VERSION ""

NS_ :

BS_:

BU_: MASTER SENSOR GEO ANDROID MOTOR

BO_ 120 HEARTBEAT: 1 MASTER
 SG_ HEARTBEAT_cmd : 0|8@1+ (1,0) [0|0] "" SENSOR,MOTOR,ANDROID,GEO

BO_ 125 MASTER_REQUEST: 1 MASTER
 SG_ MASTER_REQUEST_cmd : 0|4@1+ (1,0) [0|0] "" ANDROID

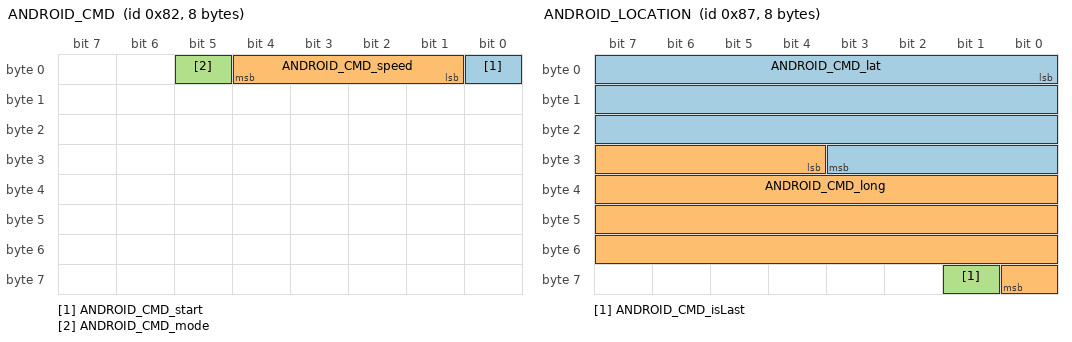
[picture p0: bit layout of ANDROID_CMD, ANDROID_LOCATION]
BO_ 130 ANDROID_CMD: 8 ANDROID
 SG_ ANDROID_CMD_start : 0|1@1+ (1,0) [0|0] "" MASTER,MOTOR
 SG_ ANDROID_CMD_speed : 1|4@1+ (1,0) [0|0] "kmph" MASTER,MOTOR
 SG_ ANDROID_CMD_mode : 5|1@1+ (1,0) [0|0] "" MASTER,MOTOR

BO_ 135 ANDROID_LOCATION: 8 ANDROID
 SG_ ANDROID_CMD_lat : 0|28@1+ (0.000001,-90.000000) [-90|90] "Degrees" MASTER,MOTOR,GEO
 SG_ ANDROID_CMD_long : 28|29@1+ (0.000001,-180.000000) [-180|180] "Degrees" MASTER,MOTOR,GEO
 SG_ ANDROID_CMD_isLast : 57|1@1+ (1,0) [0|0] "" MASTER,MOTOR,GEO

BO_ 140 CAR_CONTROL: 2 MASTER
 SG_ CAR_CONTROL_speed : 0|8@1+ (1,0) [0|0] "mph" MOTOR
 SG_ CAR_CONTROL_steer : 8|8@1+ (1,0) [0|0] "" MOTOR

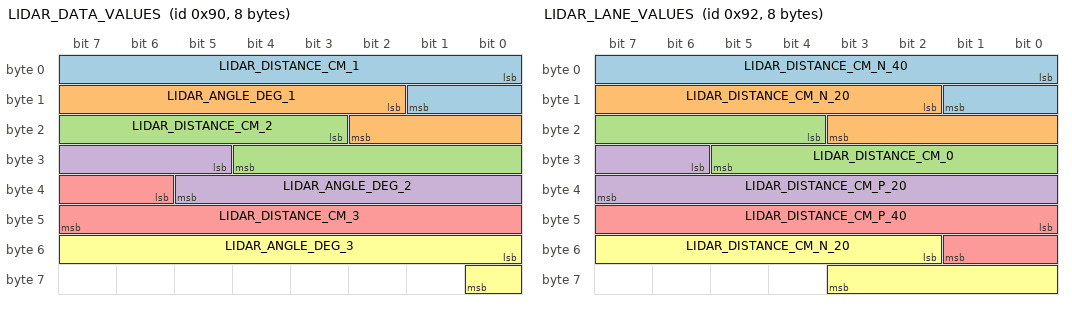
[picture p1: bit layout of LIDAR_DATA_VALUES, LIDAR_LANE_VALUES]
BO_ 144 LIDAR_DATA_VALUES: 8 SENSOR
 SG_ LIDAR_DISTANCE_CM_1 : 0|10@1+ (1,0) [0|600] "" MASTER,MOTOR,ANDROID
 SG_ LIDAR_ANGLE_DEG_1 : 10|9@1+ (1,0) [0|360] "" MASTER,MOTOR,ANDROID
 SG_ LIDAR_DISTANCE_CM_2 : 19|10@1+ (1,0) [0|600] "" MASTER,MOTOR,ANDROID
 SG_ LIDAR_ANGLE_DEG_2 : 29|9@1+ (1,0) [0|360] "" MASTER,MOTOR,ANDROID
 SG_ LIDAR_DISTANCE_CM_3 : 38|10@1+ (1,0) [0|600] "" MASTER,MOTOR,ANDROID
 SG_ LIDAR_ANGLE_DEG_3 : 48|9@1+ (1,0) [0|360] "" MASTER,MOTOR,ANDROID

BO_ 145 SENSOR_VALUES: 4 SENSOR
 SG_ LIDAR_DISTANCE_CM : 0|10@1+ (1,0) [0|600] "" MASTER,MOTOR,ANDROID
 SG_ LIDAR_ANGLE_DEG : 10|9@1+ (1,0) [0|360] "" MASTER,MOTOR,ANDROID
 SG_ LIDAR_QUALITY_DEG : 19|10@1+ (1,0) [0|128] "" MASTER,MOTOR,ANDROID
 SG_ LIDAR_DISTANCE_CM_P_180 : 30|10@1+ (1,0) [0|600] "" MASTER,MOTOR,ANDROID
 SG_ LIDAR_DISTANCE_CM_N_160 : 40|10@1+ (1,0) [0|600] "" MASTER,MOTOR,ANDROID
 SG_ LIDAR_DISTANCE_CM_N_140 : 50|10@1+ (1,0) [0|600] "" MASTER,MOTOR,ANDROID

BO_ 146 LIDAR_LANE_VALUES: 8 SENSOR
 SG_ LIDAR_DISTANCE_CM_N_40 : 0|10@1+ (1,0) [0|600] "" MASTER,MOTOR,ANDROID
 SG_ LIDAR_DISTANCE_CM_N_20 : 10|10@1+ (1,0) [0|600] "" MASTER,MOTOR,ANDROID
 SG_ LIDAR_DISTANCE_CM_0 : 20|10@1+ (1,0) [0|600] "" MASTER,MOTOR,ANDROID
 SG_ LIDAR_DISTANCE_CM_P_20 : 30|10@1+ (1,0) [0|600] "" MASTER,MOTOR,ANDROID
 SG_ LIDAR_DISTANCE_CM_P_40 : 40|10@1+ (1,0) [0|600] "" MASTER,MOTOR,ANDROID
 SG_ LIDAR_DISTANCE_CM_N_20 : 50|10@1+ (1,0) [0|600] "" MASTER,MOTOR,ANDROID
BO_ 150 SENSOR_DATA: 4 SENSOR
 SG_ LIDAR_neg160 : 0|1@1+ (1,0) [0|1] "" MASTER,MOTOR,ANDROID
 SG_ LIDAR_neg140 : 1|1@1+ (1,0) [0|1] "" MASTER,MOTOR,ANDROID
 SG_ LIDAR_neg120 : 2|1@1+ (1,0) [0|1] "" MASTER,MOTOR,ANDROID
 SG_ LIDAR_neg100 : 3|1@1+ (1,0) [0|1] "" MASTER,MOTOR,ANDROID
 SG_ LIDAR_neg80 : 4|1@1+ (1,0) [0|1] "" MASTER,MOTOR,ANDROID
 SG_ LIDAR_neg60 : 5|1@1+ (1,0) [0|1] "" MASTER,MOTOR,ANDROID
 SG_ LIDAR_neg40 : 6|1@1+ (1,0) [0|1] "" MASTER,MOTOR,ANDROID
 SG_ LIDAR_neg20 : 7|1@1+ (1,0) [0|1] "" MASTER,MOTOR,ANDROID
 SG_ LIDAR_0 : 8|1@1+ (1,0) [0|1] "" MASTER,MOTOR,ANDROID
 SG_ LIDAR_20 : 9|1@1+ (1,0) [0|1] "" MASTER,MOTOR,ANDROID
 SG_ LIDAR_40 : 10|1@1+ (1,0) [0|1] "" MASTER,MOTOR,ANDROID
 SG_ LIDAR_60 : 11|1@1+ (1,0) [0|1] "" MASTER,MOTOR,ANDROID
 SG_ LIDAR_80 : 12|1@1+ (1,0) [0|1] "" MASTER,MOTOR,ANDROID
 SG_ LIDAR_100 : 13|1@1+ (1,0) [0|1] "" MASTER,MOTOR,ANDROID
 SG_ LIDAR_120 : 14|1@1+ (1,0) [0|1] "" MASTER,MOTOR,ANDROID
 SG_ LIDAR_140 : 15|1@1+ (1,0) [0|1] "" MASTER,MOTOR,ANDROID
 SG_ LIDAR_160 : 16|1@1+ (1,0) [0|1] "" MASTER,MOTOR,ANDROID
 SG_ LIDAR_180 : 17|1@1+ (1,0) [0|1] "" MASTER,MOTOR,ANDROID
 SG_ SONAR_front : 18|10@1+ (1,0) [0|645] "" MASTER,MOTOR,ANDROID

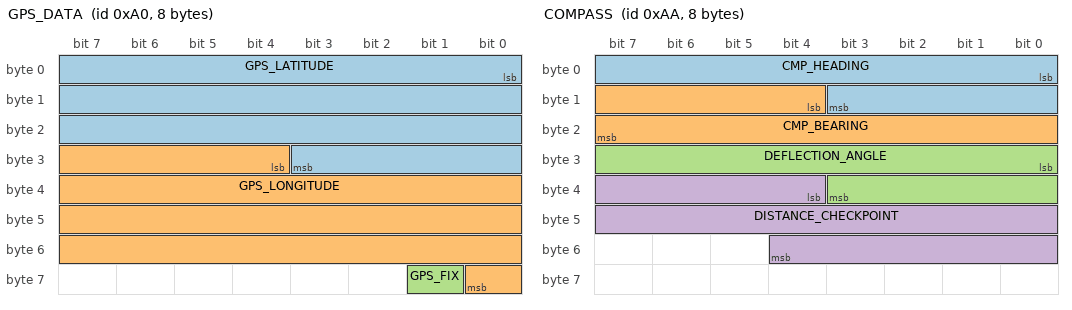
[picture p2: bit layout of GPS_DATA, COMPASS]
BO_ 160 GPS_DATA: 8 GEO
 SG_ GPS_LATITUDE : 0|28@1+ (0.000001,-90.000000) [-90|90] "Degrees" MASTER,MOTOR,ANDROID
 SG_ GPS_LONGITUDE : 28|29@1+ (0.000001,-180.000000) [-180|180] "Degrees" MASTER,MOTOR,ANDROID
 SG_ GPS_FIX : 57|1@1+ (1,0) [0|1] "" MASTER,MOTOR,ANDROID

BO_ 170 COMPASS: 8 GEO
 SG_ CMP_HEADING : 0|12@1+ (0.1,0) [0|359.9] "Degrees" MASTER,MOTOR,ANDROID
 SG_ CMP_BEARING : 12|12@1+ (0.1,0) [0|359.9] "Degrees" MASTER,MOTOR,ANDROID
 SG_ DEFLECTION_ANGLE : 24|12@1+ (0.1,-180.0) [-180.0|180.0] "Degrees" MASTER,MOTOR,ANDROID
 SG_ DISTANCE_CHECKPOINT : 36|17@1+ (0.01,0) [0|0] "Meters" MASTER,MOTOR,ANDROID

BO_ 200 MOTOR_TELEMETRY: 8 MOTOR
 SG_ MOTOR_TELEMETRY_pwm : 0|16@1+ (0.1,0) [0|30] "PWM" MASTER,ANDROID
 SG_ MOTOR_TELEMETRY_kph : 16|16@1+ (0.1,0) [0|0] "kph" MASTER,ANDROID

CM_ BU_ MASTER "Master controller is heart of the system and will control other boards";
CM_ BU_ MOTOR "Motor will drive the wheels of car and display data on LCD";
CM_ BU_ SENSOR "Sensor will help in obstacle detection and avoidance";
CM_ BU_ GEO "Geo will help in navigation";
CM_ BU_ ANDROID "User sets destination and commands to start-stop the car";

BA_ "FieldType" SG_ 120 HEARTBEAT_cmd "HEARTBEAT_cmd";

VAL_ 120 HEARTBEAT_cmd 2 "HEARTBEAT_cmd_REBOOT" 1 "HEARTBEAT_cmd_SYNC" 0 "HEARTBEAT_cmd_NOOP" ;
